# AT32UC3L016 device description
Architecture: AVR32_UC3; Family: AVR UC3
Registers are 32-bit, read-write, reset 0x0 unless marked. A register's access mark holds for its fields unless they carry their own. Offsets are from the block's base; [hi:lo] are bit positions; lines under a group give offsets from that group; {n}, {i} and the like mark numbered series; 'fields as' and 'values as' point back to an identical list.

## PDCA — Peripheral DMA Controller
Instances: PDCA 0xffff0000
{0x0+0x40*i} channel[{i}] (i=0..31) group
  0x00 MAR — Memory Address Register
    [31:0] MADDR — Memory Address
  0x04 PSR — Peripheral Select Register
    [7:0] PID — Peripheral Identifier
  0x08 TCR — Transfer Counter Register
    [15:0] TCV — Transfer Counter Value
  0x0C MARR — Memory Address Reload Register
    [31:0] MARV — Memory Address Reload Value
  0x10 TCRR — Transfer Counter Reload Register
    [15:0] TCRV — Transfer Counter Reload Value
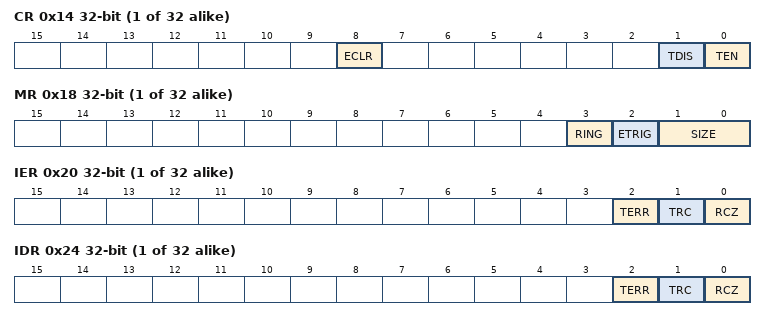
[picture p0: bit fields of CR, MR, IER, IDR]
  0x14 CR wo — Control Register
    [8] ECLR — Error Clear
    [1] TDIS — Transfer Disable
    [0] TEN — Transfer Enable
  0x18 MR — Mode Register
    [3] RING — Ring Buffer
    [2] ETRIG — Event trigger
    [1:0] SIZE — Transfer size
      0=Byte; 1=Half_Word; 2=Word
  0x1C SR ro — Status Register
    [0] TEN — Transfer Enabled
  0x20 IER wo — Interrupt Enable Register
    [2] TERR — Transfer Error
    [1] TRC — Transfer Complete
    [0] RCZ — Reload Counter Zero
  0x24 IDR wo — Interrupt Disable Register
    fields as channel[0].IER
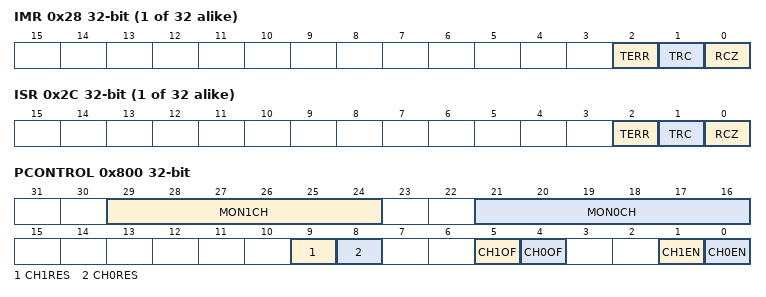
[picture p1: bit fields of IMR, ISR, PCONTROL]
  0x28 IMR ro — Interrupt Mask Register
    fields as channel[0].IER
  0x2C ISR ro — Interrupt Status Register
    fields as channel[0].IER
0x800 PCONTROL — Performance Control Register
  [29:24] MON1CH — PDCA Channel to monitor with counter 1
  [21:16] MON0CH — PDCA Channel to monitor with counter 0
  [9] CH1RES — Channel 1 counter reset
  [8] CH0RES — Channel 0 counter reset
  [5] CH1OF — Channel 1 overflow freeze
  [4] CH0OF — Channel 0 Overflow Freeze
  [1] CH1EN — Channel 1 Enabled.
  [0] CH0EN — Channel 0 Enabled
0x804 PRDATA0 ro — Channel 0 Read Data Cycles
  [31:0] DATA — Data Cycles Counted Since Last reset
0x808 PRSTALL0 ro — Channel 0 Read Stall Cycles
  [31:0] STALL — Stall Cycles counted since last reset
0x80C PRLAT0 ro — Channel 0 Read Max Latency
  [15:0] LAT — Maximum Transfer Initiation cycles counted since last reset
0x810 PWDATA0 ro — Channel 0 Write Data Cycles
  [31:0] DATA — Data Cycles Counted since last Reset
0x814 PWSTALL0 ro — Channel 0 Write Stall Cycles
  [31:0] STALL — Stall cycles counted since last reset
0x818 PWLAT0 ro — Channel0 Write Max Latency
  [15:0] LAT — Maximum transfer initiation cycles counted since last reset
0x81C PRDATA1 ro — Channel 1 Read Data Cycles
  [31:0] DATA — Data Cycles Counted Since Last reset
0x820 PRSTALL1 ro — Channel Read Stall Cycles
  [31:0] STALL — Stall Cycles Counted since last reset
0x824 PRLAT1 ro — Channel 1 Read Max Latency
  [15:0] LAT — Maximum Transfer initiation cycles counted since last reset
0x828 PWDATA1 ro — Channel 1 Write Data Cycles
  [31:0] DATA — Data cycles Counted Since last reset
0x82C PWSTALL1 ro — Channel 1 Write stall Cycles
  [31:0] STALL — Stall cycles counted since last reset
0x830 PWLAT1 ro — Channel 1 Read Max Latency
  fields as PWLAT0
0x834 VERSION ro reset 0x120

## PM — Power Manager
Instances: PM 0xffff1400
0x00 MCCTRL — Main Clock Control
  [2:0] MCSEL — Main Clock Select
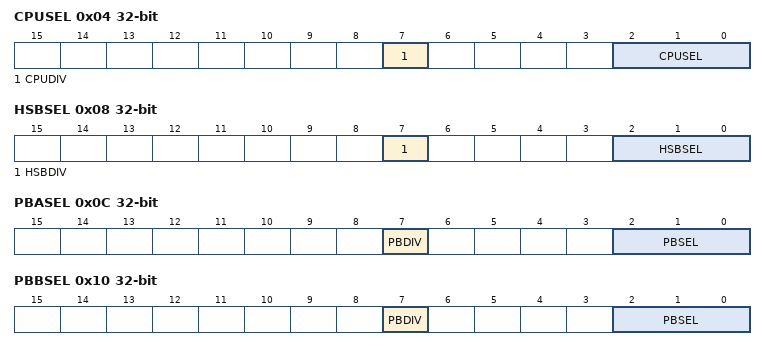
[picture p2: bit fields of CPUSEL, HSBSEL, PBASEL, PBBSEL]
0x04 CPUSEL — CPU Clock Select
  [7] CPUDIV — CPU Division Select
  [2:0] CPUSEL — CPU Clock Select
0x08 HSBSEL — HSB Clock Select
  [7] HSBDIV — HSB Division Select
  [2:0] HSBSEL — HSB Clock Select
0x0C PBASEL — PBA Clock Select
  [7] PBDIV — PB Division Select
  [2:0] PBSEL — PB Clock Select
0x10 PBBSEL — PBB Clock Select
  [7] PBDIV — PB Division Select
  [2:0] PBSEL — PB Clock Select
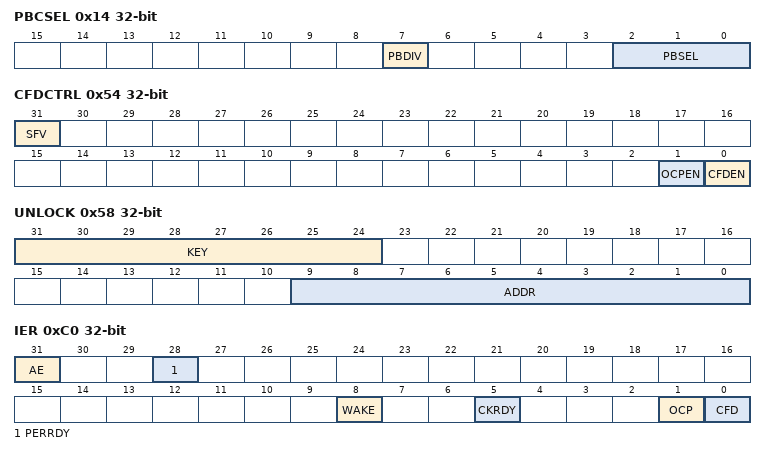
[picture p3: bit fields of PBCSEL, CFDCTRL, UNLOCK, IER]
0x14 PBCSEL — PBC Clock Select
  [7] PBDIV, [2:0] PBSEL
0x20 CPUMASK reset not defined
0x24 HSBMASK reset not defined
0x28 PBAMASK reset not defined
0x2C PBBMASK reset not defined
0x30 PBCMASK reset not defined
0x40 PBADIVMASK reset not defined — PBAQ dvi mask
0x44 PBBDIVMASK reset not defined — PBBQ dvi mask
0x48 PBCDIVMASK reset not defined — PBCQ dvi mask
0x54 CFDCTRL — Clock Failure Detector Control
  [31] SFV — Stor final value
  [1] OCPEN — Over Clock Protection Enable
  [0] CFDEN — Clock Failure Detection Enable
0x58 UNLOCK wo
  [31:24] KEY — Unlock Key
  [9:0] ADDR — Unlock Address
0xC0 IER wo — PM Interrupt Enable Register
  [31] AE — Access Error
  [28] PERRDY — Peripheral ready
  [8] WAKE — Wake pin asserted
  [5] CKRDY — Clock Ready
  [1] OCP — Over Clock Detected
  [0] CFD — Clock Failure Detected
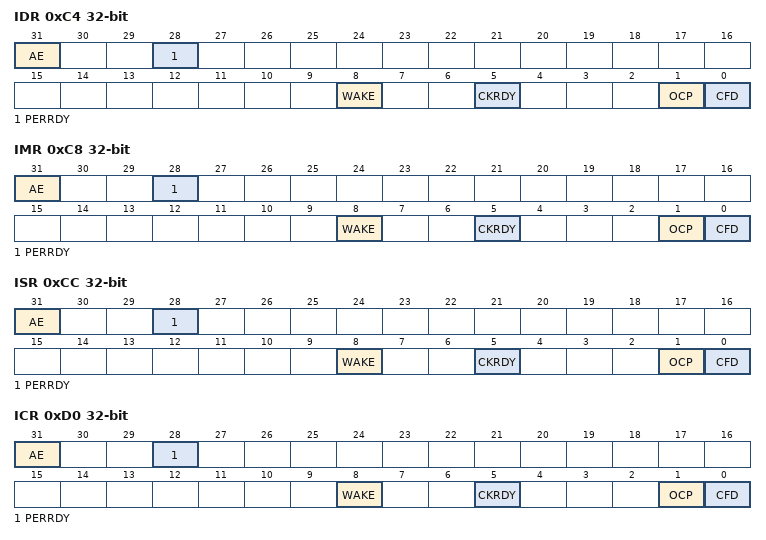
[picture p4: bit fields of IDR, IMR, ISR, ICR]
0xC4 IDR wo — PM Interrupt Disable Register
  [31] AE — Access Error
  [28] PERRDY — Peripheral Ready
  [8] WAKE — Wake pin asserted
  [5] CKRDY — Clock Ready
  [1] OCP — Over Clock Detected
  [0] CFD — Clock Failure Detected
0xC8 IMR ro — PM Interrupt Mask Register
  fields as IDR
0xCC ISR ro — PM Interrupt Status Register
  fields as IDR
0xD0 ICR wo — PM Interrupt Clear Register
  fields as IDR
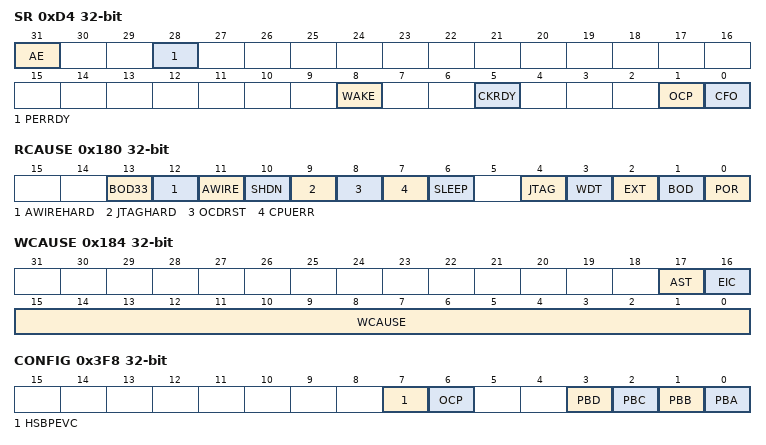
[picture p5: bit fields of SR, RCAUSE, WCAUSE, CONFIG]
0xD4 SR ro — Status Register
  [31] AE — Access Error
  [28] PERRDY — Peripheral Ready
  [8] WAKE — Wake pin asserted
  [5] CKRDY — Clock Ready
  [1] OCP — Over Clock Detected
  [0] CFO — Clock Failure Detected
0x160 PPCR reset not defined — Peripheral Power Control Register
0x180 RCAUSE ro — Reset Cause Register
  [13] BOD33 — Brown-out 3.3V Reset
  [12] AWIREHARD — AWire Hard Reset
  [11] AWIRE
  [10] SHDN — Shutdown Controller
  [9] JTAGHARD — JTAG Hard Reset
  [8] OCDRST — OCD Reset
  [7] CPUERR — CPU Error
  [6] SLEEP
  [4] JTAG — JTAG reset
  [3] WDT — Watchdog Reset
  [2] EXT — External Reset Pin
  [1] BOD — Brown-out Reset
  [0] POR — Power-on Reset
0x184 WCAUSE ro — Wake Cause Register
  [17] AST — Asynchronous Timer
  [16] EIC — External Interrupt Controller
  [15:0] WCAUSE — Wake Cause
0x188 AWEN — Asynchronous Wake Enable
  [31:0] AWEN — Aynchronous Wake Enabled
0x3F8 CONFIG ro reset not defined — Configureation Register
  [7] HSBPEVC — HSB PEVC Clock Implemented
  [6] OCP — Over Clock Protection Implemented
  [3] PBD — PBD Implemented
  [2] PBC — PBC Implemented
  [1] PBB — PBB Implemented
  [0] PBA — PBA Implemented
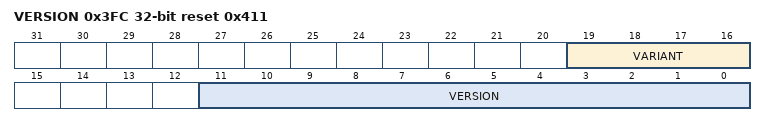
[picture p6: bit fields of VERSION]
0x3FC VERSION ro reset 0x411
  [19:16] VARIANT — Variant number
  [11:0] VERSION — Version number
